# iND83216 register map
Vendor: Indiemicro; Series: RealplumTiny; File version: 1.00
CPU: CM0 r0p1, selectable endian, no MPU, no FPU, 4 interrupt priority bits
Registers are 32-bit, read-write, no defined reset value unless marked. A register's access mark holds for its fields unless they carry their own. Offsets are from the block's base; [hi:lo] are bit positions.

## PWM_AUX — Control (and status) registers for the pulse width modulation waveform generator.
Base 0x50010800; register names take the prefix PWM_AUX_
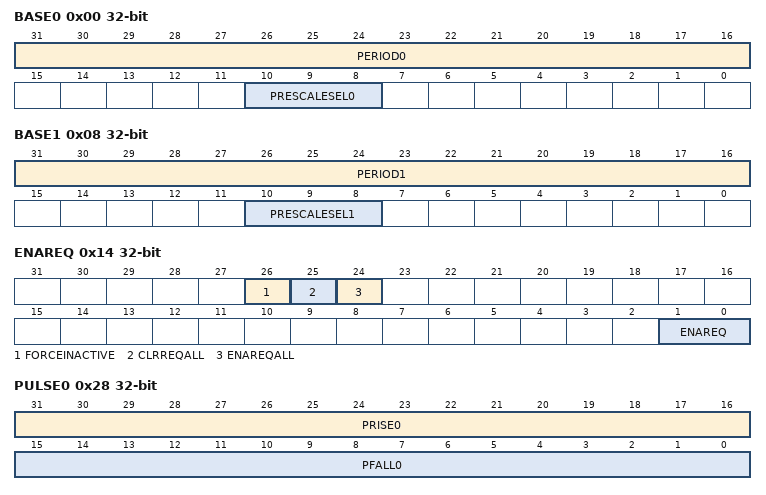
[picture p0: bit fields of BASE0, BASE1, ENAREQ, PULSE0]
0x00 BASE0 — Base 0 functions
  [31:16] PERIOD0 — Period. Specifies the period of the output waveform in terms of a number of prescaler output cycles.
  [10:8] PRESCALESEL0 — Prescaler select. Defines the ratio between the system clock and the clock used for the waveform generator.0x0: Divide by 10x1: Divide by 20x2: Divide by 40x3: Divide by 80x4: Divide by 160x5: Divide by 640x6: Divide by 2560x7: Divide by 1024
0x04 PWMCNT0 — PWM Count Value
  [15:0] PWMCNT0 ro — PWM counter value to give a sense about the current period
0x08 BASE1 — Base 1 functions
  [31:16] PERIOD1 — Period. Specifies the period of the output waveform in terms of a number of prescaler output cycles.
  [10:8] PRESCALESEL1 — Prescaler select. Defines the ratio between the system clock and the clock used for the waveform generator.0x0: Divide by 10x1: Divide by 20x2: Divide by 40x3: Divide by 80x4: Divide by 160x5: Divide by 640x6: Divide by 2560x7: Divide by 1024
0x0C PWMCNT1 — PWM Count Value
  [15:0] PWMCNT1 ro — PWM counter value to give a sense about the current period
0x10 BASESEL — Base Timer Select for individual Channels
  [1:0] BASE_SEL — Base Timer Selects:1=Select BASE1, 0=Select BASE0.
0x14 ENAREQ — Enable request
  [26] FORCEINACTIVE — Set to force PWM signals return to initial value immediately.
  [25] CLRREQALL wo — Write 1 to clear all ENA_REQ bits; Write 0 has no effects.
  [24] ENAREQALL wo — Write 1 to enable all ENA_REQ bits; Write 0 has no effects.
  [1:0] ENAREQ — Set to enable the waveform generator.
0x18 ENASTS — Enable status
  [1:0] ENASTS ro — Status of enable in the waveform generator.
0x1C INIT — Intial State of Outputs
  [1:0] INIT — Set to initialise the output waveform.
0x20 INV — Invert
  [1:0] INVERT — Set to invert the output waveform.
0x24 UPDATE
  [1:0] UPDATE — Set to trigger consumption of new PULSE parameters (invert,prescale_sel,period,pulse start & stop). The flag is automatically cleared by the hardware when the settings are consumed, so reading a high value indicates that an update is still pending.
0x28 PULSE0 — PWM0 pulse setup
  [31:16] PRISE0 — Pulse Rise. Specifies the pulse rise of the output waveform in terms of a number of prescaler output cycles. However, if INVERT is set it determines the pulse fall timing.
  [15:0] PFALL0 — Pulse Fall. Specifies the pulse fall of the output waveform in terms of a number of prescaler output cycles. However, if INVERT is set it determines the pulse rise timing.
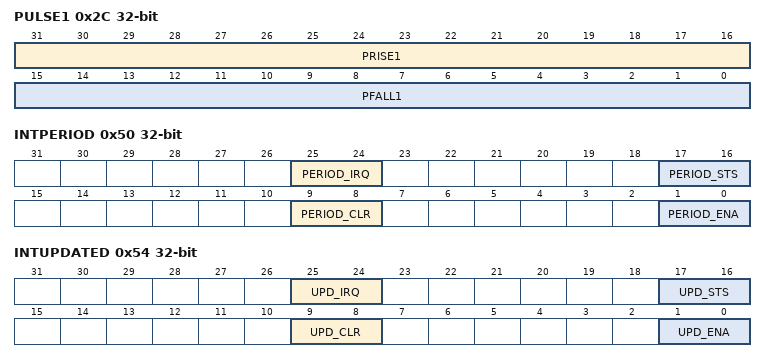
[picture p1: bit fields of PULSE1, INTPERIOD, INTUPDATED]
0x2C PULSE1 — PWM1 pulse setup
  [31:16] PRISE1 — Pulse Rise. Specifies the pulse rise of the output waveform in terms of a number of prescaler output cycles. However, if INVERT is set it determines the pulse fall timing.
  [15:0] PFALL1 — Pulse Fall. Specifies the pulse fall of the output waveform in terms of a number of prescaler output cycles. However, if INVERT is set it determines the pulse rise timing.
0x30 INTPOSEDGENA — PWM posedge interrupt enable
  [1:0] INTPOSEDGENA — Interrupt enable. bit[1:0]: posedge interrupt enable.
0x34 INTNEGEDGENA — PWM negedge interrupt enable
  [1:0] INTNEGEDGENA — Interrupt enable. bit[1:0]: negedge interrupt enable.
0x38 INTPOSEDGCLR — PWM posedge interrupt control
  [1:0] INTPOSEDGCLR wo — Interrupt clear. bit[1:0] : posedge interrupt clear.
0x3C INTNEGEDGCLR — PWM negedge interrupt control
  [1:0] INTNEGEDGCLR wo — Interrupt clear. bit[1:0] : negedge interrupt clear.
0x40 INTPOSEDGSTS — PWM posedge interrupt status
  [1:0] INTPOSEDGSTS ro — Interrupt status. bit[1:0] : posedge interrupt status.
0x44 INTNEGEDGSTS — PWM negedge interrupt status
  [1:0] INTNEGEDGSTS ro — Interrupt status. bit[1:0] : negedge interrupt status.
0x48 INTPOSEDGIRQ — PWM posedge interrupt active
  [1:0] INTPOSEDGIRQ ro — Interrupt active. bit[1:0] : posedge interrupt active.
0x4C INTNEGEDGIRQ — PWM negedge interrupt active
  [1:0] INTNEGEDGIRQ ro — Interrupt active. bit[1:0] : negedge interrupt active.
0x50 INTPERIOD — PWM Period interrupt control
  [25:24] PERIOD_IRQ ro — Period Interrupt active.
  [17:16] PERIOD_STS ro — Period Interrupt status.
  [9:8] PERIOD_CLR wo — Period Interrupt clear.
  [1:0] PERIOD_ENA — Period Interrupt enable.
0x54 INTUPDATED — PWM Updated interrupt control
  [25:24] UPD_IRQ ro — Updated Interrupt active.
  [17:16] UPD_STS ro — Updated Interrupt status.
  [9:8] UPD_CLR wo — Updated Interrupt clear.
  [1:0] UPD_ENA — Updated Interrupt enable.
